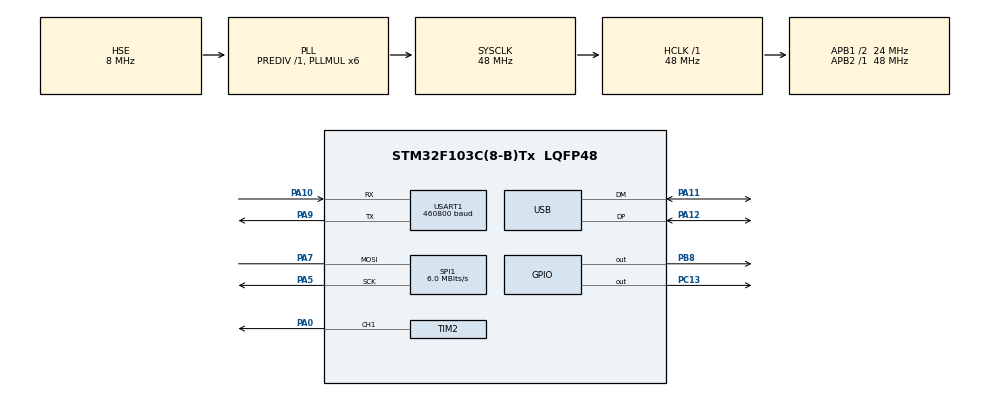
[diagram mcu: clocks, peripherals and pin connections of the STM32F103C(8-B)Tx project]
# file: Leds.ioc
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Dma.Request0=SPI1_TX
Dma.SPI1_TX.0.Direction=DMA_MEMORY_TO_PERIPH
Dma.SPI1_TX.0.Instance=DMA1_Channel3
Dma.SPI1_TX.0.MemDataAlignment=DMA_MDATAALIGN_BYTE
Dma.SPI1_TX.0.MemInc=DMA_MINC_ENABLE
Dma.SPI1_TX.0.Mode=DMA_NORMAL
Dma.SPI1_TX.0.PeriphDataAlignment=DMA_PDATAALIGN_BYTE
Dma.SPI1_TX.0.PeriphInc=DMA_PINC_DISABLE
Dma.SPI1_TX.0.Priority=DMA_PRIORITY_VERY_HIGH
Mcu.Family=STM32F1
Mcu.Name=STM32F103C(8-B)Tx
Mcu.Package=LQFP48
NVIC.DMA1_Channel3_IRQn=true\:0\:0\:false\:false\:true\:false\:true
NVIC.PriorityGroup=NVIC_PRIORITYGROUP_4
NVIC.USART1_IRQn=true\:0\:0\:false\:false\:true\:true\:true
NVIC.USB_LP_CAN1_RX0_IRQn=true\:0\:0\:false\:false\:true\:false\:true
PA0-WKUP.Signal=S_TIM2_CH1_ETR
PA10.Mode=Asynchronous
PA10.Signal=USART1_RX
PA11.Mode=Device
PA11.Signal=USB_DM
PA12.Mode=Device
PA12.Signal=USB_DP
PA13.Mode=Serial_Wire
PA13.Signal=SYS_JTMS-SWDIO
PA14.Mode=Serial_Wire
PA14.Signal=SYS_JTCK-SWCLK
PA5.Mode=Simplex_Bidirectional_Master
PA5.Signal=SPI1_SCK
PA7.Mode=Simplex_Bidirectional_Master
PA7.Signal=SPI1_MOSI
PA9.Mode=Asynchronous
PA9.Signal=USART1_TX
PB8.Signal=GPIO_Output
PC13-TAMPER-RTC.Signal=GPIO_Output
PC14-OSC32_IN.Mode=LSE-External-Oscillator
PC14-OSC32_IN.Signal=RCC_OSC32_IN
PC15-OSC32_OUT.Mode=LSE-External-Oscillator
PC15-OSC32_OUT.Signal=RCC_OSC32_OUT
PD0-OSC_IN.Mode=HSE-External-Oscillator
PD0-OSC_IN.Signal=RCC_OSC_IN
PD1-OSC_OUT.Mode=HSE-External-Oscillator
PD1-OSC_OUT.Signal=RCC_OSC_OUT
ProjectManager.HeapSize=0x200
ProjectManager.StackSize=0x400
ProjectManager.TargetToolchain=STM32CubeIDE
RCC.AHBFreq_Value=48000000
RCC.APB1CLKDivider=RCC_HCLK_DIV2
RCC.APB1Freq_Value=24000000
RCC.APB1TimFreq_Value=48000000
RCC.APB2Freq_Value=48000000
RCC.APB2TimFreq_Value=48000000
RCC.HCLKFreq_Value=48000000
RCC.PLLMUL=RCC_PLL_MUL6
RCC.PLLSourceVirtual=RCC_PLLSOURCE_HSE
RCC.SYSCLKFreq_VALUE=48000000
RCC.SYSCLKSource=RCC_SYSCLKSOURCE_PLLCLK
RCC.USBFreq_Value=48000000
SH.S_TIM2_CH1_ETR.0=TIM2_CH1,PWM Generation1 CH1
SPI1.BaudRatePrescaler=SPI_BAUDRATEPRESCALER_8
SPI1.CLKPolarity=SPI_POLARITY_LOW
SPI1.CalculateBaudRate=6.0 MBits/s
SPI1.Direction=SPI_DIRECTION_1LINE
SPI1.Mode=SPI_MODE_MASTER
SPI1.VirtualType=VM_MASTER
TIM2.Channel-PWM\ Generation1\ CH1=TIM_CHANNEL_1
USART1.BaudRate=460800
USART1.VirtualMode=VM_ASYNC
USB_DEVICE.APP_RX_DATA_SIZE=512
USB_DEVICE.APP_TX_DATA_SIZE=512
USB_DEVICE.CLASS_NAME_FS=CDC
USB_DEVICE.MANUFACTURER_STRING=Razi91
USB_DEVICE.PRODUCT_STRING_CDC_FS=wsb2812b
USB_DEVICE.USBD_DEBUG_LEVEL=0
USB_DEVICE.VirtualMode=Cdc
USB_DEVICE.VirtualModeFS=Cdc_FS
VP_USB_DEVICE_VS_USB_DEVICE_CDC_FS.Mode=CDC_FS
board=custom

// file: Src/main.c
/* USER CODE BEGIN Header */
/**
 ******************************************************************************
 * @file           : main.c
 * @brief          : Main program body
 ******************************************************************************
 * @attention
 *
 * <h2><center>&copy; Copyright (c) 2019 STMicroelectronics.
 * All rights reserved.</center></h2>
 *
 * This software component is licensed by ST under Ultimate Liberty license
 * SLA0044, the "License"; You may not use this file except in compliance with
 * the License. You may obtain a copy of the License at:
 *                             www.st.com/SLA0044
 *
 ******************************************************************************
 */
/* USER CODE END Header */
#include "main.h"
#include "usb_device.h"

/* USER CODE BEGIN Includes */
#include <usbd_core.h>
#include <math.h>
#include "program.h"
/* USER CODE END Includes */

SPI_HandleTypeDef hspi1;
DMA_HandleTypeDef hdma_spi1_tx;

TIM_HandleTypeDef htim2;

void SystemClock_Config(void);
static void MX_GPIO_Init(void);
static void MX_DMA_Init(void);
static void MX_SPI1_Init(void);
static void MX_USART1_UART_Init(void);
static void MX_TIM2_Init(void);

int main(void)
{

  /* MCU Configuration--------------------------------------------------------*/

  /* Reset of all peripherals, Initializes the Flash interface and the Systick. */
  HAL_Init();

  /* Configure the system clock */
  SystemClock_Config();

  /* Initialize all configured peripherals */
  MX_GPIO_Init();
  MX_DMA_Init();
  MX_SPI1_Init();
  MX_USART1_UART_Init();
  MX_USB_DEVICE_Init();
  MX_TIM2_Init();
  /* USER CODE BEGIN 2 */
	HAL_GPIO_WritePin(GPIOC, GPIO_PIN_13, GPIO_PIN_RESET);
  /* USER CODE END 2 */

  /* Infinite loop */
  /* USER CODE BEGIN WHILE */
	HAL_Delay(128);
	HAL_GPIO_WritePin(GPIOC, GPIO_PIN_13, GPIO_PIN_SET);
	HAL_GPIO_WritePin(GPIOB, GPIO_PIN_9, GPIO_PIN_SET);
	run();

    /* USER CODE END WHILE */

}

void SystemClock_Config(void)
{
  RCC_OscInitTypeDef RCC_OscInitStruct = {0};
  RCC_ClkInitTypeDef RCC_ClkInitStruct = {0};
  RCC_PeriphCLKInitTypeDef PeriphClkInit = {0};

  /** Initializes the RCC Oscillators according to the specified parameters
  * in the RCC_OscInitTypeDef structure.
  */
  RCC_OscInitStruct.OscillatorType = RCC_OSCILLATORTYPE_HSE;
  RCC_OscInitStruct.HSEState = RCC_HSE_ON;
  RCC_OscInitStruct.HSEPredivValue = RCC_HSE_PREDIV_DIV1;
  RCC_OscInitStruct.HSIState = RCC_HSI_ON;
  RCC_OscInitStruct.PLL.PLLState = RCC_PLL_ON;
  RCC_OscInitStruct.PLL.PLLSource = RCC_PLLSOURCE_HSE;
  RCC_OscInitStruct.PLL.PLLMUL = RCC_PLL_MUL6;
  if (HAL_RCC_OscConfig(&RCC_OscInitStruct) != HAL_OK)
  {
    Error_Handler();
  }
  /** Initializes the CPU, AHB and APB buses clocks
  */
  RCC_ClkInitStruct.ClockType = RCC_CLOCKTYPE_HCLK|RCC_CLOCKTYPE_SYSCLK
                              |RCC_CLOCKTYPE_PCLK1|RCC_CLOCKTYPE_PCLK2;
  RCC_ClkInitStruct.SYSCLKSource = RCC_SYSCLKSOURCE_PLLCLK;
  RCC_ClkInitStruct.AHBCLKDivider = RCC_SYSCLK_DIV1;
  RCC_ClkInitStruct.APB1CLKDivider = RCC_HCLK_DIV2;
  RCC_ClkInitStruct.APB2CLKDivider = RCC_HCLK_DIV1;

  if (HAL_RCC_ClockConfig(&RCC_ClkInitStruct, FLASH_LATENCY_1) != HAL_OK)
  {
    Error_Handler();
  }
  PeriphClkInit.PeriphClockSelection = RCC_PERIPHCLK_USB;
  PeriphClkInit.UsbClockSelection = RCC_USBCLKSOURCE_PLL;
  if (HAL_RCCEx_PeriphCLKConfig(&PeriphClkInit) != HAL_OK)
  {
    Error_Handler();
  }
}

static void MX_SPI1_Init(void)
{

  /* SPI1 parameter configuration*/
  hspi1.Instance = SPI1;
  hspi1.Init.Mode = SPI_MODE_MASTER;
  hspi1.Init.Direction = SPI_DIRECTION_1LINE;
  hspi1.Init.DataSize = SPI_DATASIZE_8BIT;
  hspi1.Init.CLKPolarity = SPI_POLARITY_LOW;
  hspi1.Init.CLKPhase = SPI_PHASE_1EDGE;
  hspi1.Init.NSS = SPI_NSS_SOFT;
  hspi1.Init.BaudRatePrescaler = SPI_BAUDRATEPRESCALER_8;
  hspi1.Init.FirstBit = SPI_FIRSTBIT_MSB;
  hspi1.Init.TIMode = SPI_TIMODE_DISABLE;
  hspi1.Init.CRCCalculation = SPI_CRCCALCULATION_DISABLE;
  hspi1.Init.CRCPolynomial = 10;
  if (HAL_SPI_Init(&hspi1) != HAL_OK)
  {
    Error_Handler();
  }

}

static void MX_TIM2_Init(void)
{

  TIM_MasterConfigTypeDef sMasterConfig = {0};
  TIM_OC_InitTypeDef sConfigOC = {0};

  htim2.Instance = TIM2;
  htim2.Init.Prescaler = 0;
  htim2.Init.CounterMode = TIM_COUNTERMODE_UP;
  htim2.Init.Period = 65535;
  htim2.Init.ClockDivision = TIM_CLOCKDIVISION_DIV1;
  htim2.Init.AutoReloadPreload = TIM_AUTORELOAD_PRELOAD_DISABLE;
  if (HAL_TIM_PWM_Init(&htim2) != HAL_OK)
  {
    Error_Handler();
  }
  sMasterConfig.MasterOutputTrigger = TIM_TRGO_RESET;
  sMasterConfig.MasterSlaveMode = TIM_MASTERSLAVEMODE_DISABLE;
  if (HAL_TIMEx_MasterConfigSynchronization(&htim2, &sMasterConfig) != HAL_OK)
  {
    Error_Handler();
  }
  sConfigOC.OCMode = TIM_OCMODE_PWM1;
  sConfigOC.Pulse = 0;
  sConfigOC.OCPolarity = TIM_OCPOLARITY_HIGH;
  sConfigOC.OCFastMode = TIM_OCFAST_DISABLE;
  if (HAL_TIM_PWM_ConfigChannel(&htim2, &sConfigOC, TIM_CHANNEL_1) != HAL_OK)
  {
    Error_Handler();
  }
  HAL_TIM_MspPostInit(&htim2);

}

static void MX_USART1_UART_Init(void)
{

  LL_USART_InitTypeDef USART_InitStruct = {0};

  LL_GPIO_InitTypeDef GPIO_InitStruct = {0};

  /* Peripheral clock enable */
  LL_APB2_GRP1_EnableClock(LL_APB2_GRP1_PERIPH_USART1);

  LL_APB2_GRP1_EnableClock(LL_APB2_GRP1_PERIPH_GPIOA);
  /**USART1 GPIO Configuration
  PA9   ------> USART1_TX
  PA10   ------> USART1_RX
  */
  GPIO_InitStruct.Pin = LL_GPIO_PIN_9;
  GPIO_InitStruct.Mode = LL_GPIO_MODE_ALTERNATE;
  GPIO_InitStruct.Speed = LL_GPIO_SPEED_FREQ_HIGH;
  GPIO_InitStruct.OutputType = LL_GPIO_OUTPUT_PUSHPULL;
  LL_GPIO_Init(GPIOA, &GPIO_InitStruct);

  GPIO_InitStruct.Pin = LL_GPIO_PIN_10;
  GPIO_InitStruct.Mode = LL_GPIO_MODE_FLOATING;
  LL_GPIO_Init(GPIOA, &GPIO_InitStruct);

  /* USART1 interrupt Init */
  NVIC_SetPriority(USART1_IRQn, NVIC_EncodePriority(NVIC_GetPriorityGrouping(),0, 0));
  NVIC_EnableIRQ(USART1_IRQn);

  USART_InitStruct.BaudRate = 460800;
  USART_InitStruct.DataWidth = LL_USART_DATAWIDTH_8B;
  USART_InitStruct.StopBits = LL_USART_STOPBITS_1;
  USART_InitStruct.Parity = LL_USART_PARITY_NONE;
  USART_InitStruct.TransferDirection = LL_USART_DIRECTION_TX_RX;
  USART_InitStruct.HardwareFlowControl = LL_USART_HWCONTROL_NONE;
  USART_InitStruct.OverSampling = LL_USART_OVERSAMPLING_16;
  LL_USART_Init(USART1, &USART_InitStruct);
  LL_USART_ConfigAsyncMode(USART1);
  LL_USART_Enable(USART1);
  /* USER CODE BEGIN USART1_Init 2 */
  LL_USART_EnableIT_RXNE(USART1);

  /* USER CODE END USART1_Init 2 */

}

static void MX_DMA_Init(void)
{

  /* DMA controller clock enable */
  __HAL_RCC_DMA1_CLK_ENABLE();

  /* DMA interrupt init */
  /* DMA1_Channel3_IRQn interrupt configuration */
  HAL_NVIC_SetPriority(DMA1_Channel3_IRQn, 0, 0);
  HAL_NVIC_EnableIRQ(DMA1_Channel3_IRQn);

}

static void MX_GPIO_Init(void)
{
  GPIO_InitTypeDef GPIO_InitStruct = {0};

  /* GPIO Ports Clock Enable */
  __HAL_RCC_GPIOC_CLK_ENABLE();
  __HAL_RCC_GPIOD_CLK_ENABLE();
  __HAL_RCC_GPIOA_CLK_ENABLE();
  __HAL_RCC_GPIOB_CLK_ENABLE();

  /*Configure GPIO pin Output Level */
  HAL_GPIO_WritePin(GPIOC, GPIO_PIN_13, GPIO_PIN_RESET);

  /*Configure GPIO pin Output Level */
  HAL_GPIO_WritePin(GPIOB, GPIO_PIN_8, GPIO_PIN_RESET);

  /*Configure GPIO pin : PC13 */
  GPIO_InitStruct.Pin = GPIO_PIN_13;
  GPIO_InitStruct.Mode = GPIO_MODE_OUTPUT_PP;
  GPIO_InitStruct.Pull = GPIO_NOPULL;
  GPIO_InitStruct.Speed = GPIO_SPEED_FREQ_LOW;
  HAL_GPIO_Init(GPIOC, &GPIO_InitStruct);

  /*Configure GPIO pin : PB8 */
  GPIO_InitStruct.Pin = GPIO_PIN_8;
  GPIO_InitStruct.Mode = GPIO_MODE_OUTPUT_PP;
  GPIO_InitStruct.Pull = GPIO_NOPULL;
  GPIO_InitStruct.Speed = GPIO_SPEED_FREQ_LOW;
  HAL_GPIO_Init(GPIOB, &GPIO_InitStruct);

}

void Error_Handler(void)
{
}

/************************ (C) COPYRIGHT STMicroelectronics *****END OF FILE****/
